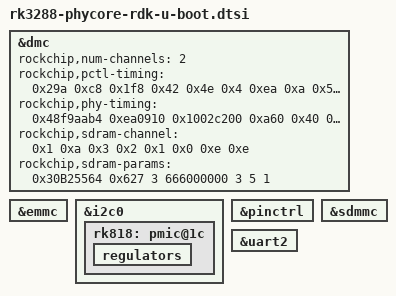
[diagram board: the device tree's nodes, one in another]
// SPDX-License-Identifier: GPL-2.0+

#include "rk3288-u-boot.dtsi"

&dmc {
	rockchip,num-channels = <2>;
	rockchip,pctl-timing = <0x29a 0xc8 0x1f8 0x42 0x4e 0x4 0xea 0xa
		0x5 0x0 0xa 0x7 0x19 0x24 0xa 0x7
		0x5 0xa 0x5 0x200 0x5 0x10 0x40 0x0
		0x1 0x7 0x7 0x4 0xc 0x43 0x100 0x0
		0x5 0x0>;
	rockchip,phy-timing = <0x48f9aab4 0xea0910 0x1002c200
		0xa60 0x40 0x10 0x0>;
	rockchip,sdram-channel = /bits/ 8 <0x1 0xa 0x3 0x2 0x1 0x0 0xe 0xe>;
	rockchip,sdram-params = <0x30B25564 0x627 3 666000000 3 5 1>;
};

&emmc {
	bootph-all;
};

&i2c0 {
	bootph-all;

	rk818: pmic@1c {
		bootph-all;

		regulators {
			bootph-all;
		};
	};
};

&pinctrl {
	bootph-all;
};

&sdmmc {
	bootph-all;
};

&uart2 {
	bootph-all;
};
